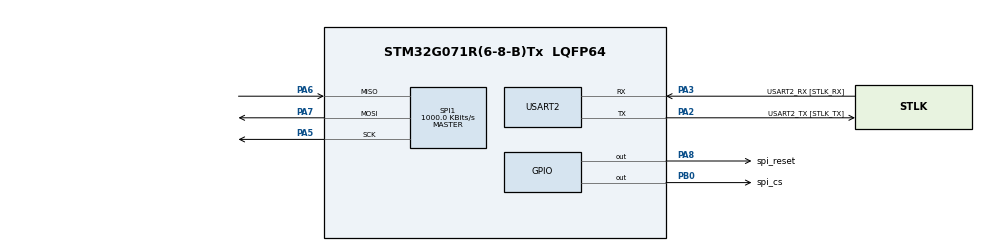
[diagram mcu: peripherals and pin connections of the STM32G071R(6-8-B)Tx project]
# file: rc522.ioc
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Mcu.Family=STM32G0
Mcu.Name=STM32G071R(6-8-B)Tx
Mcu.Package=LQFP64
PA13.GPIO_Label=TMS
PA13.Mode=Serial_Wire
PA13.Signal=SYS_SWDIO
PA14-BOOT0.GPIO_Label=TCK
PA14-BOOT0.Mode=Serial_Wire
PA14-BOOT0.Signal=SYS_SWCLK
PA2.GPIO_Label=USART2_TX [STLK_TX]
PA2.GPIO_PuPd=GPIO_PULLUP
PA2.Mode=Asynchronous
PA2.Signal=USART2_TX
PA3.GPIO_Label=USART2_RX [STLK_RX]
PA3.GPIO_PuPd=GPIO_PULLUP
PA3.Mode=Asynchronous
PA3.Signal=USART2_RX
PA5.Mode=Full_Duplex_Master
PA5.Signal=SPI1_SCK
PA6.Mode=Full_Duplex_Master
PA6.Signal=SPI1_MISO
PA7.Mode=Full_Duplex_Master
PA7.Signal=SPI1_MOSI
PA8.GPIO_Label=spi_reset
PA8.Signal=GPIO_Output
PB0.GPIO_Label=spi_cs
PB0.Signal=GPIO_Output
PC13.Mode=SYS_WakeUp1
PC13.Signal=SYS_WKUP2
PC14-OSC32_IN\ (PC14).Mode=LSE-External-Oscillator
PC14-OSC32_IN\ (PC14).Signal=RCC_OSC32_IN
PC15-OSC32_OUT\ (PC15).Mode=LSE-External-Oscillator
PC15-OSC32_OUT\ (PC15).Signal=RCC_OSC32_OUT
PF0-OSC_IN\ (PF0).GPIO_Label=MCO
PF0-OSC_IN\ (PF0).Mode=HSE-External-Oscillator
PF0-OSC_IN\ (PF0).Signal=RCC_OSC_IN
PF1-OSC_OUT\ (PF1).Mode=HSE-External-Oscillator
PF1-OSC_OUT\ (PF1).Signal=RCC_OSC_OUT
ProjectManager.HeapSize=0x200
ProjectManager.StackSize=0x400
ProjectManager.TargetToolchain=STM32CubeIDE
RCC.ADCFreq_Value=64000000
RCC.AHBFreq_Value=64000000
RCC.CortexFreq_Value=64000000
RCC.EXTERNAL_CLOCK_VALUE=12288000
RCC.HCLKFreq_Value=64000000
RCC.HSE_VALUE=8000000
RCC.HSI_VALUE=16000000
RCC.SYSCLKFreq_VALUE=64000000
RCC.SYSCLKSource=RCC_SYSCLKSOURCE_PLLCLK
RCC.VCOOutputFreq_Value=128000000
SPI1.BaudRatePrescaler=SPI_BAUDRATEPRESCALER_64
SPI1.CLKPhase=SPI_PHASE_1EDGE
SPI1.CalculateBaudRate=1000.0 KBits/s
SPI1.DataSize=SPI_DATASIZE_8BIT
SPI1.Direction=SPI_DIRECTION_2LINES
SPI1.Mode=SPI_MODE_MASTER
SPI1.VirtualType=VM_MASTER
USART2.VirtualMode-Asynchronous=VM_ASYNC
board=NUCLEO-G071RB

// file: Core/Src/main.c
/* USER CODE BEGIN Header */
/**
  ******************************************************************************
  * @file           : main.c
  * @brief          : Main program body
  ******************************************************************************
  * @attention
  *
  * Copyright (c) 2026 STMicroelectronics.
  * All rights reserved.
  *
  * This software is licensed under terms that can be found in the LICENSE file
  * in the root directory of this software component.
  * If no LICENSE file comes with this software, it is provided AS-IS.
  *
  ******************************************************************************
  */
/* USER CODE END Header */
#include "main.h"

/* USER CODE BEGIN Includes */

#include "MFRC522_STM32.h"
#include "stdio.h"

/* USER CODE END Includes */

void SystemClock_Config(void);
static void MX_GPIO_Init(void);
static void MX_USART2_UART_Init(void);
static void MX_SPI1_Init(void);

/* USER CODE BEGIN 0 */

uint8_t uid[4];
MFRC522_t rfID = {SPI1, spi_cs_GPIO_Port, spi_cs_Pin, spi_reset_GPIO_Port, spi_reset_Pin};

/* USER CODE END 0 */

int main(void)
{

  /* MCU Configuration--------------------------------------------------------*/

  /* Reset of all peripherals, Initializes the Flash interface and the Systick. */
  LL_APB2_GRP1_EnableClock(LL_APB2_GRP1_PERIPH_SYSCFG);
  LL_APB1_GRP1_EnableClock(LL_APB1_GRP1_PERIPH_PWR);

  /* Configure the system clock */
  SystemClock_Config();

  /* Initialize all configured peripherals */
  MX_GPIO_Init();
  MX_USART2_UART_Init();
  MX_SPI1_Init();
  /* USER CODE BEGIN 2 */

  MFRC522_Init(&rfID);

  /* USER CODE END 2 */

  /* Infinite loop */
  while (1)
  {

	  if (waitcardDetect(&rfID) == STATUS_OK) {

	      MFRC522_ReadUid(&rfID, uid);

	      waitcardRemoval(&rfID);
	  }
	  LL_mDelay(2000);

  }
}

void SystemClock_Config(void)
{
  LL_FLASH_SetLatency(LL_FLASH_LATENCY_2);
  while(LL_FLASH_GetLatency() != LL_FLASH_LATENCY_2)
  {
  }

  /* HSI configuration and activation */
  LL_RCC_HSI_Enable();
  while(LL_RCC_HSI_IsReady() != 1)
  {
  }

  /* Main PLL configuration and activation */
  LL_RCC_PLL_ConfigDomain_SYS(LL_RCC_PLLSOURCE_HSI, LL_RCC_PLLM_DIV_1, 8, LL_RCC_PLLR_DIV_2);
  LL_RCC_PLL_Enable();
  LL_RCC_PLL_EnableDomain_SYS();
  while(LL_RCC_PLL_IsReady() != 1)
  {
  }

  /* Set AHB prescaler*/
  LL_RCC_SetAHBPrescaler(LL_RCC_SYSCLK_DIV_1);

  /* Sysclk activation on the main PLL */
  LL_RCC_SetSysClkSource(LL_RCC_SYS_CLKSOURCE_PLL);
  while(LL_RCC_GetSysClkSource() != LL_RCC_SYS_CLKSOURCE_STATUS_PLL)
  {
  }

  /* Set APB1 prescaler*/
  LL_RCC_SetAPB1Prescaler(LL_RCC_APB1_DIV_1);
  LL_Init1msTick(64000000);
  /* Update CMSIS variable (which can be updated also through SystemCoreClockUpdate function) */
  LL_SetSystemCoreClock(64000000);
}

static void MX_SPI1_Init(void)
{

  LL_SPI_InitTypeDef SPI_InitStruct = {0};

  LL_GPIO_InitTypeDef GPIO_InitStruct = {0};

  /* Peripheral clock enable */
  LL_APB2_GRP1_EnableClock(LL_APB2_GRP1_PERIPH_SPI1);

  LL_IOP_GRP1_EnableClock(LL_IOP_GRP1_PERIPH_GPIOA);
  /**SPI1 GPIO Configuration
  PA5   ------> SPI1_SCK
  PA6   ------> SPI1_MISO
  PA7   ------> SPI1_MOSI
  */
  GPIO_InitStruct.Pin = LL_GPIO_PIN_5;
  GPIO_InitStruct.Mode = LL_GPIO_MODE_ALTERNATE;
  GPIO_InitStruct.Speed = LL_GPIO_SPEED_FREQ_LOW;
  GPIO_InitStruct.OutputType = LL_GPIO_OUTPUT_PUSHPULL;
  GPIO_InitStruct.Pull = LL_GPIO_PULL_NO;
  GPIO_InitStruct.Alternate = LL_GPIO_AF_0;
  LL_GPIO_Init(GPIOA, &GPIO_InitStruct);

  GPIO_InitStruct.Pin = LL_GPIO_PIN_6;
  GPIO_InitStruct.Mode = LL_GPIO_MODE_ALTERNATE;
  GPIO_InitStruct.Speed = LL_GPIO_SPEED_FREQ_LOW;
  GPIO_InitStruct.OutputType = LL_GPIO_OUTPUT_PUSHPULL;
  GPIO_InitStruct.Pull = LL_GPIO_PULL_NO;
  GPIO_InitStruct.Alternate = LL_GPIO_AF_0;
  LL_GPIO_Init(GPIOA, &GPIO_InitStruct);

  GPIO_InitStruct.Pin = LL_GPIO_PIN_7;
  GPIO_InitStruct.Mode = LL_GPIO_MODE_ALTERNATE;
  GPIO_InitStruct.Speed = LL_GPIO_SPEED_FREQ_LOW;
  GPIO_InitStruct.OutputType = LL_GPIO_OUTPUT_PUSHPULL;
  GPIO_InitStruct.Pull = LL_GPIO_PULL_NO;
  GPIO_InitStruct.Alternate = LL_GPIO_AF_0;
  LL_GPIO_Init(GPIOA, &GPIO_InitStruct);

  /* SPI1 parameter configuration*/
  SPI_InitStruct.TransferDirection = LL_SPI_FULL_DUPLEX;
  SPI_InitStruct.Mode = LL_SPI_MODE_MASTER;
  SPI_InitStruct.DataWidth = LL_SPI_DATAWIDTH_8BIT;
  SPI_InitStruct.ClockPolarity = LL_SPI_POLARITY_LOW;
  SPI_InitStruct.ClockPhase = LL_SPI_PHASE_1EDGE;
  SPI_InitStruct.NSS = LL_SPI_NSS_SOFT;
  SPI_InitStruct.BaudRate = LL_SPI_BAUDRATEPRESCALER_DIV64;
  SPI_InitStruct.BitOrder = LL_SPI_MSB_FIRST;
  SPI_InitStruct.CRCCalculation = LL_SPI_CRCCALCULATION_DISABLE;
  SPI_InitStruct.CRCPoly = 7;
  LL_SPI_Init(SPI1, &SPI_InitStruct);
  LL_SPI_SetStandard(SPI1, LL_SPI_PROTOCOL_MOTOROLA);
  LL_SPI_EnableNSSPulseMgt(SPI1);

}

static void MX_USART2_UART_Init(void)
{

  LL_USART_InitTypeDef USART_InitStruct = {0};

  LL_GPIO_InitTypeDef GPIO_InitStruct = {0};

  LL_RCC_SetUSARTClockSource(LL_RCC_USART2_CLKSOURCE_PCLK1);

  /* Peripheral clock enable */
  LL_APB1_GRP1_EnableClock(LL_APB1_GRP1_PERIPH_USART2);

  LL_IOP_GRP1_EnableClock(LL_IOP_GRP1_PERIPH_GPIOA);
  /**USART2 GPIO Configuration
  PA2   ------> USART2_TX
  PA3   ------> USART2_RX
  */
  GPIO_InitStruct.Pin = USART2_TX_Pin;
  GPIO_InitStruct.Mode = LL_GPIO_MODE_ALTERNATE;
  GPIO_InitStruct.Speed = LL_GPIO_SPEED_FREQ_LOW;
  GPIO_InitStruct.OutputType = LL_GPIO_OUTPUT_PUSHPULL;
  GPIO_InitStruct.Pull = LL_GPIO_PULL_UP;
  GPIO_InitStruct.Alternate = LL_GPIO_AF_1;
  LL_GPIO_Init(USART2_TX_GPIO_Port, &GPIO_InitStruct);

  GPIO_InitStruct.Pin = USART2_RX_Pin;
  GPIO_InitStruct.Mode = LL_GPIO_MODE_ALTERNATE;
  GPIO_InitStruct.Speed = LL_GPIO_SPEED_FREQ_LOW;
  GPIO_InitStruct.OutputType = LL_GPIO_OUTPUT_PUSHPULL;
  GPIO_InitStruct.Pull = LL_GPIO_PULL_UP;
  GPIO_InitStruct.Alternate = LL_GPIO_AF_1;
  LL_GPIO_Init(USART2_RX_GPIO_Port, &GPIO_InitStruct);

  USART_InitStruct.PrescalerValue = LL_USART_PRESCALER_DIV1;
  USART_InitStruct.BaudRate = 115200;
  USART_InitStruct.DataWidth = LL_USART_DATAWIDTH_8B;
  USART_InitStruct.StopBits = LL_USART_STOPBITS_1;
  USART_InitStruct.Parity = LL_USART_PARITY_NONE;
  USART_InitStruct.TransferDirection = LL_USART_DIRECTION_TX_RX;
  USART_InitStruct.HardwareFlowControl = LL_USART_HWCONTROL_NONE;
  USART_InitStruct.OverSampling = LL_USART_OVERSAMPLING_16;
  LL_USART_Init(USART2, &USART_InitStruct);
  LL_USART_SetTXFIFOThreshold(USART2, LL_USART_FIFOTHRESHOLD_1_8);
  LL_USART_SetRXFIFOThreshold(USART2, LL_USART_FIFOTHRESHOLD_1_8);
  LL_USART_DisableFIFO(USART2);
  LL_USART_ConfigAsyncMode(USART2);

  LL_USART_Enable(USART2);

  /* Polling USART2 initialisation */
  while((!(LL_USART_IsActiveFlag_TEACK(USART2))) || (!(LL_USART_IsActiveFlag_REACK(USART2))))
  {
  }

}

static void MX_GPIO_Init(void)
{
  LL_GPIO_InitTypeDef GPIO_InitStruct = {0};

  /* GPIO Ports Clock Enable */
  LL_IOP_GRP1_EnableClock(LL_IOP_GRP1_PERIPH_GPIOC);
  LL_IOP_GRP1_EnableClock(LL_IOP_GRP1_PERIPH_GPIOF);
  LL_IOP_GRP1_EnableClock(LL_IOP_GRP1_PERIPH_GPIOA);
  LL_IOP_GRP1_EnableClock(LL_IOP_GRP1_PERIPH_GPIOB);

  /**/
  LL_GPIO_ResetOutputPin(spi_cs_GPIO_Port, spi_cs_Pin);

  /**/
  LL_GPIO_ResetOutputPin(spi_reset_GPIO_Port, spi_reset_Pin);

  /**/
  GPIO_InitStruct.Pin = spi_cs_Pin;
  GPIO_InitStruct.Mode = LL_GPIO_MODE_OUTPUT;
  GPIO_InitStruct.Speed = LL_GPIO_SPEED_FREQ_LOW;
  GPIO_InitStruct.OutputType = LL_GPIO_OUTPUT_PUSHPULL;
  GPIO_InitStruct.Pull = LL_GPIO_PULL_NO;
  LL_GPIO_Init(spi_cs_GPIO_Port, &GPIO_InitStruct);

  /**/
  GPIO_InitStruct.Pin = spi_reset_Pin;
  GPIO_InitStruct.Mode = LL_GPIO_MODE_OUTPUT;
  GPIO_InitStruct.Speed = LL_GPIO_SPEED_FREQ_LOW;
  GPIO_InitStruct.OutputType = LL_GPIO_OUTPUT_PUSHPULL;
  GPIO_InitStruct.Pull = LL_GPIO_PULL_NO;
  LL_GPIO_Init(spi_reset_GPIO_Port, &GPIO_InitStruct);

}

void Error_Handler(void)
{
  __disable_irq();
  while (1)
  {
  }
}
